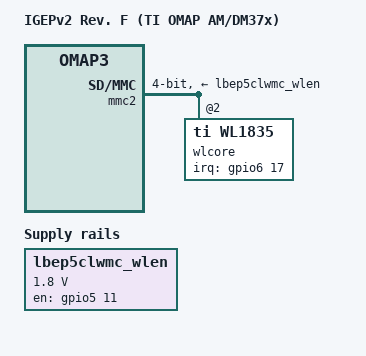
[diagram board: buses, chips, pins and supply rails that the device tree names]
/*
 * Device Tree Source for IGEPv2 Rev. F (TI OMAP AM/DM37x)
 *
 * Copyright (C) 2012 Javier Martinez Canillas <javier@osg.samsung.com>
 * Copyright (C) 2012 Enric Balletbo i Serra <eballetbo@gmail.com>
 *
 * This program is free software; you can redistribute it and/or modify
 * it under the terms of the GNU General Public License version 2 as
 * published by the Free Software Foundation.
 */

#include "omap3-igep0020-common.dtsi"

/ {
	model = "IGEPv2 Rev. F (TI OMAP AM/DM37x)";
	compatible = "isee,omap3-igep0020-rev-f", "ti,omap36xx", "ti,omap3";

	/* Regulator to trigger the WL_EN signal of the Wifi module */
	lbep5clwmc_wlen: regulator-lbep5clwmc-wlen {
		compatible = "regulator-fixed";
		regulator-name = "regulator-lbep5clwmc-wlen";
		regulator-min-microvolt = <1800000>;
		regulator-max-microvolt = <1800000>;
		pinctrl-names = "default";
		pinctrl-0 = <&lbep5clwmc_pins>;				
		gpio = <&gpio5 11 GPIO_ACTIVE_LOW>;		/* gpio_139 - WL_EN */
		enable-active-high;
		startup-delay-us = <700000>;
	};
};

&omap3_pmx_core {

	lbep5clwmc_pins: pinmux_lbep5clwmc_pins {
		pinctrl-single,pins = <
			OMAP3_CORE1_IOPAD(0x21d4, PIN_INPUT | MUX_MODE4)	/* mcspi1_cs3.gpio_177 - W_IRQ */
			OMAP3_CORE1_IOPAD(0x2166, PIN_OUTPUT | MUX_MODE4)	/* sdmmc2_dat5.gpio_137 - BT_EN */
			OMAP3_CORE1_IOPAD(0x216a, PIN_OUTPUT | MUX_MODE4)	/* sdmmc2_dat7.gpio_139 - WL_EN */
		>;
	};

	mmc2_pins: pinmux_mmc2_pins {
		pinctrl-single,pins = <
			OMAP3_CORE1_IOPAD(0x2158, PIN_INPUT_PULLUP | MUX_MODE0)	/* sdmmc2_clk.sdmmc2_clk */
			OMAP3_CORE1_IOPAD(0x215a, PIN_INPUT_PULLUP | MUX_MODE0)	/* sdmmc2_cmd.sdmmc2_cmd */
			OMAP3_CORE1_IOPAD(0x215c, PIN_INPUT_PULLUP | MUX_MODE0) /* sdmmc2_dat0.sdmmc2_dat0 */
			OMAP3_CORE1_IOPAD(0x215e, PIN_INPUT_PULLUP | MUX_MODE0)	/* sdmmc2_dat1.sdmmc2_dat1 */
			OMAP3_CORE1_IOPAD(0x2160, PIN_INPUT_PULLUP | MUX_MODE0)	/* sdmmc2_dat2.sdmmc2_dat2 */
			OMAP3_CORE1_IOPAD(0x2162, PIN_INPUT_PULLUP | MUX_MODE0)	/* sdmmc2_dat3.sdmmc2_dat3 */
		>;
	};

	mmc2_pins_sleep: pinmux_mmc2_pins_sleep {
		pinctrl-single,pins = <
			OMAP3_CORE1_IOPAD(0x2158, PIN_INPUT_PULLUP | MUX_MODE4)	/* sdmmc2_clk.sdmmc2_clk */
			OMAP3_CORE1_IOPAD(0x215a, PIN_INPUT_PULLUP | MUX_MODE4)	/* sdmmc2_cmd.sdmmc2_cmd */
			OMAP3_CORE1_IOPAD(0x215c, PIN_INPUT_PULLUP | MUX_MODE4) /* sdmmc2_dat0.sdmmc2_dat0 */
			OMAP3_CORE1_IOPAD(0x215e, PIN_INPUT_PULLUP | MUX_MODE4)	/* sdmmc2_dat1.sdmmc2_dat1 */
			OMAP3_CORE1_IOPAD(0x2160, PIN_INPUT_PULLUP | MUX_MODE4)	/* sdmmc2_dat2.sdmmc2_dat2 */
			OMAP3_CORE1_IOPAD(0x2162, PIN_INPUT_PULLUP | MUX_MODE4)	/* sdmmc2_dat3.sdmmc2_dat3 */
		>;
	};

};

&mmc2 {
	status = "ok";
	pinctrl-names = "default", "sleep";
	pinctrl-0 = <&mmc2_pins>;
	pinctrl-1 = <&mmc2_pins_sleep>;
	vmmc-supply = <&lbep5clwmc_wlen>;
	bus-width = <4>;
	ti,non-removable;
	ti,needs-special-hs-handling;
	cap-power-off-card;
	keep-power-in-suspend;
	#dma-cells = <2>;
	#address-cells = <1>;
	#size-cells = <0>;
	wlcore: wlcore@2 {
		compatible = "ti,wl1835";
		reg = <2>;
		interrupt-parent = <&gpio6>;
		interrupts = <17 IRQ_TYPE_LEVEL_HIGH>; /* gpio 177 */
	};
};
